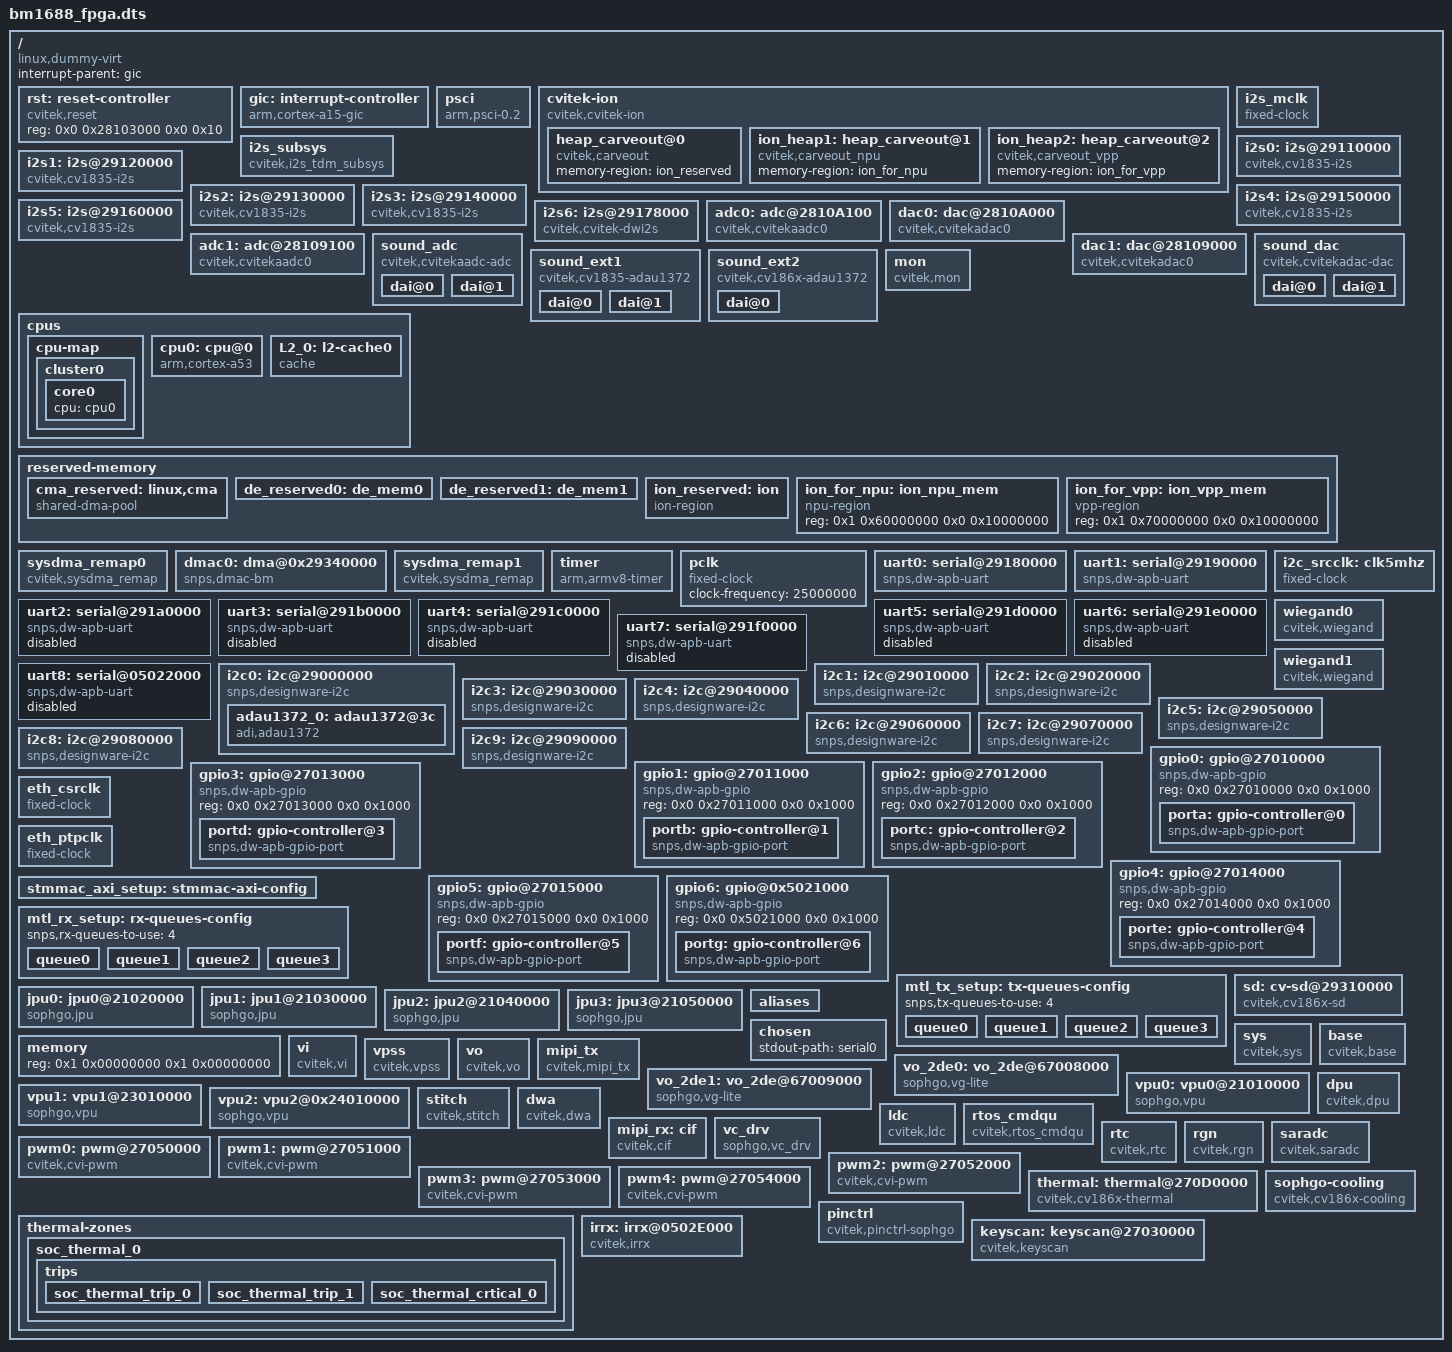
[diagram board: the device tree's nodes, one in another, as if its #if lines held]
#include <dt-bindings/interrupt-controller/arm-gic.h>
#include <dt-bindings/gpio/gpio.h>
#include <dt-bindings/reset/cv186x-resets.h>
#include <dt-bindings/dma/cv186x-dmamap.h>
#include <dt-bindings/input/input.h>

/dts-v1/;

/memreserve/	0x100000000 0x0000000000040000; // ATF BL31 + BL32

#include "soph-clocks.dtsi"
/ {
	compatible = "linux,dummy-virt";
	#size-cells = <0x2>;
	#address-cells = <0x2>;
	interrupt-parent = <&gic>;

	rst: reset-controller {
		#reset-cells = <1>;
		compatible = "cvitek,reset";
		reg = <0x0 0x28103000 0x0 0x10>;
	};

	gic: interrupt-controller {
		compatible = "arm,cortex-a15-gic";
		ranges;
		#size-cells = <0x2>;
		#address-cells = <0x2>;
		interrupt-controller;
		#interrupt-cells = <0x3>;
		reg = <0x0 0x50001000 0x0 0x1000>,
			  <0x0 0x50002000 0x0 0x2000>;
	};

	psci {
		migrate = <0xc4000005>;
		cpu_on = <0xc4000003>;
		cpu_off = <0x84000002>;
		cpu_suspend = <0xc4000001>;
		sys_poweroff = <0x84000008>;
		sys_reset = <0x84000009>;
		method = "smc";
		compatible = "arm,psci-0.2", "arm,psci";
	};

	cvitek-ion {
		compatible = "cvitek,cvitek-ion";

		heap_carveout@0 {
			compatible = "cvitek,carveout";
			memory-region = <&ion_reserved>;
		};
		#ifndef __UBOOT__
		ion_heap1: heap_carveout@1 {
			compatible = "cvitek,carveout_npu";
			memory-region = <&ion_for_npu>;
		};

		ion_heap2: heap_carveout@2 {
			compatible = "cvitek,carveout_vpp";
			memory-region = <&ion_for_vpp>;
		};
		#endif
	};

	i2s_mclk: i2s_mclk {
		clock-output-names = "i2s_mclk";
		clock-frequency = <24576000>;
		#clock-cells = <0x0>;
		compatible = "fixed-clock";
	};

	i2s_subsys {
		compatible = "cvitek,i2s_tdm_subsys";
		reg = <0x0 0x29100000 0x0 0x10000>;
		clocks = <&i2s_mclk>, <&clk CV186X_CLK_A0PLL>,
			<&clk CV186X_CLK_AUD0>, <&clk CV186X_CLK_AUD1>,
			<&clk CV186X_CLK_AUD2>, <&clk CV186X_CLK_AUD3>,
			<&clk CV186X_CLK_AUD4>, <&clk CV186X_CLK_AUD5>;
		clock-names = "i2sclk", "clk_a0pll",
			"clk_sdma_aud0", "clk_sdma_aud1",
			"clk_sdma_aud2", "clk_sdma_aud3",
			"clk_sdma_aud4", "clk_sdma_aud5";
		master_base = <0x29120000>; /* I2S1 is master, only useful while using multi I2S IPs work on same IO */
	};

	i2s0: i2s@29110000 {
		compatible = "cvitek,cv1835-i2s";
		reg = <0x0 0x29110000 0x0 0x10000>;
		clocks = <&i2s_mclk 0>;
		clock-names = "i2sclk";

		interrupts = <GIC_SPI 121 IRQ_TYPE_LEVEL_HIGH>;
		dev-id = <0>;
		#sound-dai-cells = <0>;
		dmas = <&dmac0 0 1 1>; /* read channel */
		dma-names = "rx";
		capability = "rx"; /* I2S0 connect to internal ADC as RX */
		mclk_out = "false";
	};

	i2s1: i2s@29120000 {
		compatible = "cvitek,cv1835-i2s";
		reg = <0x0 0x29120000 0x0 0x10000>;
		clocks = <&i2s_mclk 0>;
		clock-names = "i2sclk";

		interrupts = <GIC_SPI 122 IRQ_TYPE_LEVEL_HIGH>;
		dev-id = <1>;
		#sound-dai-cells = <0>;
		dmas = <&dmac0 2 1 1>; /* read channel */
		dma-names = "rx";
		capability = "rx";
		mclk_out = "false";
	};

	i2s2: i2s@29130000 {
		compatible = "cvitek,cv1835-i2s";
		reg = <0x0 0x29130000 0x0 0x10000>;
		clocks = <&i2s_mclk 0>;
		clock-names = "i2sclk";

		interrupts = <GIC_SPI 123 IRQ_TYPE_LEVEL_HIGH>;
		dev-id = <2>;
		#sound-dai-cells = <0>;
		dmas = <&dmac0 1 1 1>; /* write channel */
		dma-names = "tx";
		capability = "tx";
		mclk_out = "true";
	};

	i2s3: i2s@29140000 {
		compatible = "cvitek,cv1835-i2s";
		reg = <0x0 0x29140000 0x0 0x10000>;
		clocks = <&i2s_mclk 0>;
		clock-names = "i2sclk";

		interrupts = <GIC_SPI 124 IRQ_TYPE_LEVEL_HIGH>;
		dev-id = <3>;
		#sound-dai-cells = <0>;
		dmas = <&dmac0 4 1 1>; /* write channel */
		dma-names = "tx";
		capability = "tx"; /* I2S3 connect to internal DAC as TX */
		mclk_out = "true";
	};

	i2s4: i2s@29150000 {
		compatible = "cvitek,cv1835-i2s";
		reg = <0x0 0x29150000 0x0 0x10000>;
		clocks = <&i2s_mclk 0>;
		clock-names = "i2sclk";

		interrupts = <GIC_SPI 125 IRQ_TYPE_LEVEL_HIGH>;
		dev-id = <4>;
		#sound-dai-cells = <0>;
		dmas = <&dmac0 2 1 1>; /* read channel */
		dma-names = "rx";
		capability = "rx"; /* I2S0 connect to internal ADC as RX */
		mclk_out = "false";
	};

	i2s5: i2s@29160000 {
		compatible = "cvitek,cv1835-i2s";
		reg = <0x0 0x29160000 0x0 0x10000>;
		clocks = <&i2s_mclk 0>;
		clock-names = "i2sclk";

		interrupts = <GIC_SPI 126 IRQ_TYPE_LEVEL_HIGH>;
		dev-id = <5>;
		#sound-dai-cells = <0>;
		dmas = <&dmac0 3 1 1>; /* write channel */
		dma-names = "tx";
		capability = "tx"; /* I2S3 connect to internal DAC as TX */
		mclk_out = "true";
	};

	i2s6: i2s@29178000 {
		compatible = "cvitek,cvitek-dwi2s";
		reg = <0x0 0x29178000 0x0 0x400>;
		clocks = <&i2s_mclk 0>;
		clock-names = "i2sclk";

		interrupts = <GIC_SPI 127 IRQ_TYPE_LEVEL_HIGH>;
		dev-id = <6>;
		#sound-dai-cells = <0>;
		dmas = <&dmac0 4 1 1>; /* read channel */
		dma-names = "tx";
		capability = "tx"; /* I2S0 connect to internal ADC as RX */
		mclk_out = "true";
	};

	adc0: adc@2810A100 {
		compatible = "cvitek,cvitekaadc0";
		reg = <0x0 0x2810A100 0x0 0x100>;
		clocks = <&i2s_mclk 0>;
		clock-names = "i2sclk";
		clk_source = <0x29140000>; /* MCLK source is I2S3 */
	};

	dac0: dac@2810A000 {
		compatible = "cvitek,cvitekadac0";
		reg = <0x0 0x2810A000 0x0 0x100>;
		clocks = <&i2s_mclk 0>;
		clock-names = "i2sclk";
	};

	adc1: adc@28109100 {
		compatible = "cvitek,cvitekaadc0";
		reg = <0x0 0x28109100 0x0 0x100>;
		clocks = <&i2s_mclk 0>;
		clock-names = "i2sclk";
		clk_source = <0x29160000>; /* MCLK source is I2S3 */
	};

	dac1: dac@28109000 {
		compatible = "cvitek,cvitekadac0";
		reg = <0x0 0x28109000 0x0 0x100>;
		clocks = <&i2s_mclk 0>;
		clock-names = "i2sclk";
	};

	sound_adc {
		compatible = "cvitek,cvitekaadc-adc";
		cvi,model = "CV182XA";
		cvi,card_name = "cv186x_adc";
		dai@0 {
			//adc0:2810A100 - i2s0:29110000;
		};
		dai@1 {
			//adc1:28109100 - i2s4:29150000;
		};
	};

	sound_dac {
		compatible = "cvitek,cvitekadac-dac";
		cvi,model = "CV182XA";
		cvi,card_name = "cv186x_dac";
		dai@0 {
			//dac0:2810A000 - i2s3:29140000;
		};
		dai@1 {
			//dac0:28109000 - i2s5:29160000;
		};
	};

	sound_ext1 {
		compatible = "cvitek,cv1835-adau1372";
		cvi,model = "CV1835";
		cvi,mode = "I2S";
		cvi,fmt = "IBNF";
		cvi,card_name = "cvi_sound_card_0";
		cvi,slot_no=<2>;

		dai@0 {
			cvi,dai_name = "cv1835-i2s-2";
			cvi,stream_name = "adau1372-aif";
#if 0
			cvi,cpu_dai_name = "29130000.i2s";
			cvi,codec_dai_name = "adau1372-aif";
			cvi,platform_name = "29130000.i2s";
			cvi,codec_name = "adau1372.0-003c";
#endif
			cvi,role = "master";
		};

		dai@1 {
			cvi,dai_name = "cv1835-i2s-1";
			cvi,stream_name = "adau1372-aif";
#if 0
			cvi,cpu_dai_name = "29120000.i2s";
			cvi,codec_dai_name = "adau1372-aif";
			cvi,platform_name = "29120000.i2s";
			cvi,codec_name = "adau1372.0-003c";
#endif
			cvi,role = "slave";
		};
	};


	sound_ext2 {
		compatible = "cvitek,cv186x-adau1372";
		cvi,model = "CV1835";
		cvi,mode = "I2S";
		cvi,fmt = "NBNF";
		cvi,card_name = "cvi_cv186x_dw";
		cvi,slot_no=<2>;

		dai@0 {
			cvi,stream_name = "adau1372-aif";
			cvi,role = "master";
		};

	};

	cpus {
		#size-cells = <0x0>;
		#address-cells = <0x1>;

		cpu-map {
			cluster0 {
				core0 {
					cpu = <&cpu0>;
				};
			};
		};

		cpu0: cpu@0 {
			reg = <0x0>;
			enable-method = "psci";
			compatible = "arm,cortex-a53";
			device_type = "cpu";
			next-level-cache = <&L2_0>;
		};

		L2_0: l2-cache0 {
			compatible = "cache";
			cache-unified;
			cache-level = <2>;
		};
	};

	mon {
		compatible = "cvitek,mon";
		reg-names = "pcmon", "ddr_ctrl", "ddr_phyd", "ddr_aximon_real", "ddr_aximon_offline", "ddr_aximon_bulk", "ddr_top";
		reg = <0x0 0x01040000 0x0 0x1000>,
					<0x0 0x70004000 0x0 0x1000>,
					<0x0 0x70006000 0x0 0x1000>,
					<0x0 0x6fff3000 0x0 0x1000>,
					<0x0 0x6fff4000 0x0 0x1000>,
					<0x0 0x6fff5000 0x0 0x1000>,
					<0x0 0x7000A000 0x0 0x1000>;
		interrupts = <GIC_SPI 77 IRQ_TYPE_EDGE_RISING>;
	};

	/*pmu_a53 {
		compatible = "arm,cortex-a53-pmu";
		interrupts = <GIC_SPI 196 IRQ_TYPE_LEVEL_HIGH>,
			     <GIC_SPI 197 IRQ_TYPE_LEVEL_HIGH>,
			     <GIC_SPI 198 IRQ_TYPE_LEVEL_HIGH>,
			     <GIC_SPI 199 IRQ_TYPE_LEVEL_HIGH>,
			     <GIC_SPI 208 IRQ_TYPE_LEVEL_HIGH>,
			     <GIC_SPI 209 IRQ_TYPE_LEVEL_HIGH>,
			     <GIC_SPI 210 IRQ_TYPE_LEVEL_HIGH>,
			     <GIC_SPI 211 IRQ_TYPE_LEVEL_HIGH>;
	};*/

	reserved-memory {
		#address-cells = <0x2>;
		#size-cells = <0x2>;
		ranges;

		cma_reserved: linux,cma {
			compatible = "shared-dma-pool";
			reusable;
			//size = <0x0 0x200000>; // 2MB
			size = <0x0 0x80000000>; // 2GB
			alignment = <0x0 0x100000>; // 1MB
			linux,cma-default;
		};

		de_reserved0: de_mem0 {
			reg = <0x1 0x10000000 0x0 0x8000000>; // 128M, for 2de
			no-map;
		};

		de_reserved1: de_mem1 {
			reg = <0x1 0x18000000 0x0 0x8000000>; // 128M, for 2de
			no-map;
		};

		ion_reserved: ion {
			compatible = "ion-region";
			alloc-ranges = <0x1 0x40000000 0 0x20000000>;
			size = <0x0 0x20000000>; // 512MB
		};
		#ifndef __UBOOT__
		ion_for_npu: ion_npu_mem {
			compatible = "npu-region";
			reg = <0x1 0x60000000 0x0 0x10000000>; // 256M
		};

		ion_for_vpp: ion_vpp_mem {
			compatible = "vpp-region";
			reg = <0x1 0x70000000 0x0 0x10000000>; // 256M, for VPP/JPU
		};
		#endif
	};

	sysdma_remap0 {
		compatible = "cvitek,sysdma_remap";
		reg = <0x0 0x28100154 0x0 0x10>;
		ch-remap = <CVI_I2S0_RX CVI_I2S2_TX CVI_I2S1_RX CVI_I2S1_TX
					CVI_I2S_dw_RX CVI_I2S_dw_TX CVI_I2S2_RX CVI_I2S3_TX>;
		int_mux_base = <0x281002A0>;
		int_mux = <0x1FF>; /* enable bit [0..8] for CPU0(CA53) */
	};

	dmac0: dma@0x29340000 {
		compatible = "snps,dmac-bm";
		reg = <0x0 0x29340000 0x0 0x1000>;
		clock-names = "clk_sdma_axi";
		clocks = <&clk CV186X_CLK_SDMA0_AXI>;

		interrupts = <GIC_SPI 98 IRQ_TYPE_LEVEL_HIGH>;
		dma-channels = /bits/ 8 <8>;
		#dma-cells = <3>;
		dma-requests = /bits/ 8 <16>;
		chan_allocation_order = /bits/ 8 <0>;
		chan_priority = /bits/ 8 <1>;
		block_size = <1024>;
		dma-masters = /bits/ 8 <2>;
		data-width = <4 4>; /* bytes */
		axi_tr_width = <4>; /* bytes */
		block-ts = <15>;
	};

	sysdma_remap1 {
		compatible = "cvitek,sysdma_remap";
		reg = <0x0 0x28100164 0x0 0x10>;
		ch-remap = <CVI_I2S4_RX CVI_SPI_NAND CVI_SPI_NAND CVI_I2S5_TX
					CVI_SPI0_TX CVI_SPI0_TX CVI_SPI1_TX CVI_SPI1_TX>;
		int_mux_base = <0x281002A4>;
		int_mux = <0x1FF>; /* enable bit [0..8] for CPU0(CA53) */
	};
#if 0
	dmac1: dma@0x29350000 {
		compatible = "snps,dmac-bm";
		reg = <0x0 0x29350000 0x0 0x1000>;
		clock-names = "clk_sdma_axi";
		clocks = <&clk CV186X_CLK_SDMA1_AXI>;

		interrupts = <GIC_SPI 99 IRQ_TYPE_LEVEL_HIGH>;
		dma-channels = /bits/ 8 <8>;
		#dma-cells = <3>;
		dma-requests = /bits/ 8 <16>;
		chan_allocation_order = /bits/ 8 <0>;
		chan_priority = /bits/ 8 <1>;
		block_size = <1024>;
		dma-masters = /bits/ 8 <2>;
		data-width = <4 4>; /* bytes */
		axi_tr_width = <4>; /* bytes */
		block-ts = <15>;
	};
#endif
	timer {
		interrupts = <GIC_PPI 13 (GIC_CPU_MASK_SIMPLE(1) | IRQ_TYPE_LEVEL_LOW)>,
			<GIC_PPI 14 (GIC_CPU_MASK_SIMPLE(1) | IRQ_TYPE_LEVEL_LOW)>,
			<GIC_PPI 11 (GIC_CPU_MASK_SIMPLE(1) | IRQ_TYPE_LEVEL_LOW)>,
			<GIC_PPI 10 (GIC_CPU_MASK_SIMPLE(1) | IRQ_TYPE_LEVEL_LOW)>;
		always-on;
		clock-frequency = <5000000>;
		compatible = "arm,armv8-timer";
	};


	pclk: pclk {
		#clock-cells = <0>;
		compatible = "fixed-clock";
		clock-frequency = <25000000>;
	};

	uart0: serial@29180000 {
		compatible = "snps,dw-apb-uart";
		reg = <0x0 0x29180000 0x0 0x1000>;
		clock-frequency = <5000000>;
		current-speed = <38400>;
		interrupts = <GIC_SPI 128 IRQ_TYPE_LEVEL_HIGH>;
		reg-shift = <2>;
		reg-io-width = <4>;
		status = "okay";
	};

	uart1: serial@29190000 {
		compatible = "snps,dw-apb-uart";
		reg = <0x0 0x29190000 0x0 0x1000>;
		clock-frequency = <5000000>;
		current-speed = <38400>;
		interrupts = <GIC_SPI 129 IRQ_TYPE_LEVEL_HIGH>;
		reg-shift = <2>;
		reg-io-width = <4>;
		status = "okay";
	};

	uart2: serial@291a0000 {
		compatible = "snps,dw-apb-uart";
		reg = <0x0 0x291a0000 0x0 0x1000>;
		clock-frequency = <5000000>;
		current-speed = <38400>;
		interrupts = <GIC_SPI 130 IRQ_TYPE_LEVEL_HIGH>;
		reg-shift = <2>;
		reg-io-width = <4>;
		status = "disable";
	};

	uart3: serial@291b0000 {
		compatible = "snps,dw-apb-uart";
		reg = <0x0 0x291b0000 0x0 0x1000>;
		clock-frequency = <5000000>;
		current-speed = <38400>;
		interrupts = <GIC_SPI 131 IRQ_TYPE_LEVEL_HIGH>;
		reg-shift = <2>;
		reg-io-width = <4>;
		status = "disable";
	};

	uart4: serial@291c0000 {
		compatible = "snps,dw-apb-uart";
		reg = <0x0 0x291c0000 0x0 0x1000>;
		clock-frequency = <5000000>;
		current-speed = <38400>;
		interrupts = <GIC_SPI 132 IRQ_TYPE_LEVEL_HIGH>;
		reg-shift = <2>;
		reg-io-width = <4>;
		status = "disable";
	};

	uart5: serial@291d0000 {
		compatible = "snps,dw-apb-uart";
		reg = <0x0 0x291d0000 0x0 0x1000>;
		clock-frequency = <5000000>;
		current-speed = <38400>;
		interrupts = <GIC_SPI 133 IRQ_TYPE_LEVEL_HIGH>;
		reg-shift = <2>;
		reg-io-width = <4>;
		status = "disable";
	};

	uart6: serial@291e0000 {
		compatible = "snps,dw-apb-uart";
		reg = <0x0 0x291e0000 0x0 0x1000>;
		clock-frequency = <5000000>;
		current-speed = <38400>;
		interrupts = <GIC_SPI 134 IRQ_TYPE_LEVEL_HIGH>;
		reg-shift = <2>;
		reg-io-width = <4>;
		status = "disable";
	};

	uart7: serial@291f0000 {
		compatible = "snps,dw-apb-uart";
		reg = <0x0 0x291f0000 0x0 0x1000>;
		clock-frequency = <5000000>;
		current-speed = <38400>;
		interrupts = <GIC_SPI 135 IRQ_TYPE_LEVEL_HIGH>;
		reg-shift = <2>;
		reg-io-width = <4>;
		status = "disable";
	};

	uart8: serial@05022000 {
		compatible = "snps,dw-apb-uart";
		reg = <0x0 0x05022000 0x0 0x1000>;
		clock-frequency = <5000000>;
		current-speed = <38400>;
		interrupts = <GIC_SPI 77 IRQ_TYPE_LEVEL_HIGH>;
		reg-shift = <2>;
		reg-io-width = <4>;
		status = "disable";
	};

	i2c_srcclk: clk5mhz {
		clock-output-names = "clk5mhz";
		clock-frequency = <5000000>;
		#clock-cells = <0x0>;
		compatible = "fixed-clock";
	};

	i2c0: i2c@29000000 {
		compatible = "snps,designware-i2c";
		clocks = <&i2c_srcclk>;
		reg = <0x0 0x29000000 0x0 0x1000>;
		interrupts = <GIC_SPI 106 IRQ_TYPE_LEVEL_HIGH>;
		clock-frequency = <100000>;

		#size-cells = <0x0>;
		#address-cells = <0x1>;
		//resets = <&rst RST_I2C0>;
		// reset-names = "i2c0";

		adau1372_0: adau1372@3c{
			compatible = "adi,adau1372";
			reg = <0x3c>;
			clocks = <&i2s_mclk>;
			clock-names = "mclk";
		};
	};

	wiegand0 {
		compatible = "cvitek,wiegand";
		reg-names = "wiegand";
		reg = <0x0 0x27020000 0x0 0x1000>;
		// clocks = <&clk CV181X_CLK_WGN>, <&clk CV181X_CLK_WGN0>;
		// clock-names = "clk_wgn", "clk_wgn1";
		interrupts = <GIC_SPI 149 IRQ_TYPE_LEVEL_HIGH>;
		resets = <&rst RST_WGN0>;
		reset-names = "res_wgn";
	};

	wiegand1 {
		compatible = "cvitek,wiegand";
		reg-names = "wiegand";
		reg = <0x0 0x27021000 0x0 0x1000>;
		// clocks = <&clk CV181X_CLK_WGN>, <&clk CV181X_CLK_WGN1>;
		// clock-names = "clk_wgn", "clk_wgn1";
		interrupts = <GIC_SPI 150 IRQ_TYPE_LEVEL_HIGH>;
		resets = <&rst RST_WGN1>;
		reset-names = "res_wgn";
	};

	i2c1: i2c@29010000 {
		compatible = "snps,designware-i2c";
		clocks = <&i2c_srcclk>;
		reg = <0x0 0x29010000 0x0 0x1000>;
		interrupts = <GIC_SPI 107 IRQ_TYPE_LEVEL_HIGH>;
		clock-frequency = <100000>;

		#size-cells = <0x0>;
		#address-cells = <0x1>;
		//resets = <&rst RST_I2C1>;
		// reset-names = "i2c1";
	};

	i2c2: i2c@29020000 {
		compatible = "snps,designware-i2c";
		clocks = <&i2c_srcclk>;
		reg = <0x0 0x29020000 0x0 0x1000>;
		interrupts = <GIC_SPI 108 IRQ_TYPE_LEVEL_HIGH>;
		clock-frequency = <100000>;

		#size-cells = <0x0>;
		#address-cells = <0x1>;
		//resets = <&rst RST_I2C2>;
		// reset-names = "i2c2";
	};

	i2c3: i2c@29030000 {
		compatible = "snps,designware-i2c";
		clocks = <&i2c_srcclk>;
		reg = <0x0 0x29030000 0x0 0x1000>;
		interrupts = <GIC_SPI 109 IRQ_TYPE_LEVEL_HIGH>;
		clock-frequency = <100000>;

		#size-cells = <0x0>;
		#address-cells = <0x1>;
		//resets = <&rst RST_I2C3>;
		// reset-names = "i2c3";
	};

	i2c4: i2c@29040000 {
		compatible = "snps,designware-i2c";
		clocks = <&i2c_srcclk>;
		reg = <0x0 0x29040000 0x0 0x1000>;
		interrupts = <GIC_SPI 110 IRQ_TYPE_LEVEL_HIGH>;
		clock-frequency = <100000>;

		#size-cells = <0x0>;
		#address-cells = <0x1>;
		//resets = <&rst RST_I2C4>;
		// reset-names = "i2c4";
	};

	i2c5: i2c@29050000 {
		compatible = "snps,designware-i2c";
		clocks = <&i2c_srcclk>;
		reg = <0x0 0x29050000 0x0 0x1000>;
		interrupts = <GIC_SPI 111 IRQ_TYPE_LEVEL_HIGH>;
		clock-frequency = <100000>;

		#size-cells = <0x0>;
		#address-cells = <0x1>;
		//resets = <&rst RST_I2C5>;
		// reset-names = "i2c5";
	};

	i2c6: i2c@29060000 {
		compatible = "snps,designware-i2c";
		clocks = <&i2c_srcclk>;
		reg = <0x0 0x29060000 0x0 0x1000>;
		interrupts = <GIC_SPI 112 IRQ_TYPE_LEVEL_HIGH>;
		clock-frequency = <100000>;

		#size-cells = <0x0>;
		#address-cells = <0x1>;
		//resets = <&rst RST_I2C6>;
		// reset-names = "i2c6";
	};

	i2c7: i2c@29070000 {
		compatible = "snps,designware-i2c";
		clocks = <&i2c_srcclk>;
		reg = <0x0 0x29070000 0x0 0x1000>;
		interrupts = <GIC_SPI 113 IRQ_TYPE_LEVEL_HIGH>;
		clock-frequency = <100000>;

		#size-cells = <0x0>;
		#address-cells = <0x1>;
		//resets = <&rst RST_I2C7>;
		// reset-names = "i2c7";
	};

	i2c8: i2c@29080000 {
		compatible = "snps,designware-i2c";
		clocks = <&i2c_srcclk>;
		reg = <0x0 0x29080000 0x0 0x1000>;
		interrupts = <GIC_SPI 114 IRQ_TYPE_LEVEL_HIGH>;
		clock-frequency = <100000>;

		#size-cells = <0x0>;
		#address-cells = <0x1>;
		//resets = <&rst RST_I2C8>;
		// reset-names = "i2c8";
	};

	i2c9: i2c@29090000 {
		compatible = "snps,designware-i2c";
		clocks = <&i2c_srcclk>;
		reg = <0x0 0x29090000 0x0 0x1000>;
		interrupts = <GIC_SPI 115 IRQ_TYPE_LEVEL_HIGH>;
		clock-frequency = <100000>;

		#size-cells = <0x0>;
		#address-cells = <0x1>;
		//resets = <&rst RST_I2C9>;
		// reset-names = "i2c9";
	};

	gpio0: gpio@27010000 {
		compatible = "snps,dw-apb-gpio";
		reg = <0x0 0x27010000 0x0 0x1000>;
		#address-cells = <1>;
		#size-cells = <0>;

		porta: gpio-controller@0 {
			compatible = "snps,dw-apb-gpio-port";
			bank-name = "porta";
			gpio-controller;
			#gpio-cells = <2>;
			snps,nr-gpios = <32>;
			reg = <0>;
			interrupts = <GIC_SPI 143 IRQ_TYPE_LEVEL_HIGH>;
		};
	};

	gpio1: gpio@27011000 {
		compatible = "snps,dw-apb-gpio";
		reg = <0x0 0x27011000 0x0 0x1000>;
		#address-cells = <1>;
		#size-cells = <0>;

		portb: gpio-controller@1 {
			compatible = "snps,dw-apb-gpio-port";
			bank-name = "portb";
			gpio-controller;
			#gpio-cells = <2>;
			snps,nr-gpios = <32>;
			reg = <0>;
			interrupts = <GIC_SPI 144 IRQ_TYPE_LEVEL_HIGH>;
		};
	};

	gpio2: gpio@27012000 {
		compatible = "snps,dw-apb-gpio";
		reg = <0x0 0x27012000 0x0 0x1000>;
		#address-cells = <1>;
		#size-cells = <0>;

		portc: gpio-controller@2 {
			compatible = "snps,dw-apb-gpio-port";
			bank-name = "portc";
			gpio-controller;
			#gpio-cells = <2>;
			snps,nr-gpios = <32>;
			reg = <0>;
			interrupts = <GIC_SPI 145 IRQ_TYPE_LEVEL_HIGH>;
		};
	};

	gpio3: gpio@27013000 {
		compatible = "snps,dw-apb-gpio";
		reg = <0x0 0x27013000 0x0 0x1000>;
		#address-cells = <1>;
		#size-cells = <0>;

		portd: gpio-controller@3 {
			compatible = "snps,dw-apb-gpio-port";
			bank-name = "portd";
			gpio-controller;
			#gpio-cells = <2>;
			snps,nr-gpios = <32>;
			reg = <0>;
			interrupts = <GIC_SPI 146 IRQ_TYPE_LEVEL_HIGH>;
		};
	};

	gpio4: gpio@27014000 {
		compatible = "snps,dw-apb-gpio";
		reg = <0x0 0x27014000 0x0 0x1000>;
		#address-cells = <1>;
		#size-cells = <0>;

		porte: gpio-controller@4 {
			compatible = "snps,dw-apb-gpio-port";
			bank-name = "porte";
			gpio-controller;
			#gpio-cells = <2>;
			snps,nr-gpios = <32>;
			reg = <0>;
			interrupts = <GIC_SPI 147 IRQ_TYPE_LEVEL_HIGH>;
		};
	};

	gpio5: gpio@27015000 {
		compatible = "snps,dw-apb-gpio";
		reg = <0x0 0x27015000 0x0 0x1000>;
		#address-cells = <1>;
		#size-cells = <0>;

		portf: gpio-controller@5 {
			compatible = "snps,dw-apb-gpio-port";
			bank-name = "portf";
			gpio-controller;
			#gpio-cells = <2>;
			snps,nr-gpios = <32>;
			reg = <0>;
			interrupts = <GIC_SPI 148 IRQ_TYPE_LEVEL_HIGH>;
		};
	};

	gpio6: gpio@0x5021000 {
		compatible = "snps,dw-apb-gpio";
		reg = <0x0 0x5021000 0x0 0x1000>;
		#address-cells = <1>;
		#size-cells = <0>;

		portg: gpio-controller@6 {
			compatible = "snps,dw-apb-gpio-port";
			bank-name = "portg";
			gpio-controller;
			#gpio-cells = <2>;
			snps,nr-gpios = <32>;
			reg = <0>;
			interrupts = <GIC_SPI 76 IRQ_TYPE_LEVEL_HIGH>;
		};
	};

	eth_csrclk: eth_csrclk {
		clock-output-names = "eth_csrclk";
		clock-frequency = <250000000>;
		#clock-cells = <0x0>;
		compatible = "fixed-clock";
	};

	eth_ptpclk: eth_ptpclk {
		clock-output-names = "eth_ptpclk";
		clock-frequency = <50000000>;
		#clock-cells = <0x0>;
		compatible = "fixed-clock";
	};

	stmmac_axi_setup: stmmac-axi-config {
		snps,wr_osr_lmt = <1>;
		snps,rd_osr_lmt = <2>;
		snps,blen = <4 8 16 0 0 0 0>;
	};

	mtl_rx_setup: rx-queues-config {
		snps,rx-queues-to-use = <4>;
		queue0 {};
		queue1 {};
		queue2 {};
		queue3 {};
	};

	mtl_tx_setup: tx-queues-config {
		snps,tx-queues-to-use = <4>;
		queue0 {};
		queue1 {};
		queue2 {};
		queue3 {};
	};
#if 0
	ethernet0: ethernet@290e0000 {
		compatible = "bitmain,ethernet";
		reg = <0x0 0x290e0000 0x0 0x4000>;
		reg-names = "mac";
		interrupt-names = "macirq";
		interrupts = <GIC_SPI 104 IRQ_TYPE_LEVEL_HIGH>;
		/*
		//bm1684x
		clock-names = "clk_tx", "gate_clk_tx", "stmmaceth", "ptp_ref", "gate_clk_ref";
		clocks = <&div_clk DIV_CLK_FPLL_TX_ETH0>,
			   <&div_clk GATE_CLK_ETH0_TX>,
			   <&div_clk GATE_CLK_AXI6_ETH0>,
			   <&div_clk GATE_CLK_PTP_REF_I_ETH0>,
			   <&div_clk GATE_CLK_REF_ETH0>;
		//cv183x
		clock-names = "stmmaceth", "ptp_ref", "clk_500m_eth", "clk_axi4_eth";
		clocks = <&eth_csrclk>, <&eth_ptpclk>, <&clk CV1835_CLK_500M_ETH0>, <&clk CV1835_CLK_AXI4_ETH0>;*/
		//cv182x
		clock-names = "stmmaceth", "ptp_ref";
		clocks = <&eth_csrclk>, <&eth_ptpclk>;
#ifdef __UBOOT__
		phy-reset-gpios = <&portd 21 0>;
#endif
		/* no hash filter and perfect filter support */
		snps,multicast-filter-bins = <0>;
		snps,perfect-filter-entries = <1>;

		snps,txpbl = <32>;
		snps,rxpbl = <32>;
		snps,aal;

		snps,axi-config = <&stmmac_axi_setup>;
		snps,mtl-rx-config = <&mtl_rx_setup>;
		snps,mtl-tx-config = <&mtl_tx_setup>;

		phy-mode = "rgmii-id";
		max-speed = <100>;

	};
#endif
	sd:cv-sd@29310000 {
#ifdef	__UBOOT__
		compatible = "cvitek,cv186x-sd";
#else
		compatible = "cvitek,cv186x-fpga-sd";
#endif
		reg = <0x0 0x29310000 0x0 0x10000>;
		reg-names = "core_mem";
		interrupts = <GIC_SPI 90 IRQ_TYPE_LEVEL_HIGH>;
		bus-width = <4>;
		//cap-sd-highspeed;
		//cap-mmc-highspeed;
		no-sdio;
		no-mmc;
		no-1-8-v;
		//broken-cd;
		src-frequency = <5000000>;
		min-frequency = <200000>;
		max-frequency = <4000000>;
		reset_tx_rx_phy;
		reset-names = "sdhci";
		64_addressing;
	};

	jpu0: jpu0@21020000 {
	    compatible = "sophgo,jpu";
	    reg =  <0x0 0x21020000 0x0 0x10000>;
	    interrupts =   <GIC_SPI 46 IRQ_TYPE_EDGE_RISING>;
	    dev-id = <0>;
	};

	jpu1: jpu1@21030000 {
	    compatible = "sophgo,jpu";
	    reg =  <0x0 0x21030000 0x0 0x10000>;
	    interrupts =   <GIC_SPI 47 IRQ_TYPE_EDGE_RISING>;
	    dev-id = <1>;
	};

	jpu2: jpu2@21040000 {
	    compatible = "sophgo,jpu";
	    reg =  <0x0 0x21040000 0x0 0x10000>;
	    interrupts =   <GIC_SPI 48 IRQ_TYPE_EDGE_RISING>;
	    dev-id = <2>;
	};

	jpu3: jpu3@21050000 {
	    compatible = "sophgo,jpu";
	    reg =  <0x0 0x21050000 0x0 0x10000>;
	    interrupts =   <GIC_SPI 49 IRQ_TYPE_EDGE_RISING>;
	    dev-id = <3>;
	};

	memory {
		reg = <0x1 0x00000000 0x1 0x00000000>;	//4G
		device_type = "memory";
	};

	aliases {
		serial0 = &uart0;
		serial1 = &uart1;
		serial2 = &uart2;
		serial3 = &uart3;
		serial4 = &uart4;
		serial5 = &uart5;
		serial6 = &uart6;
		serial7 = &uart7;
	};

	chosen {
		stdout-path = "serial0"; // "serial0:115200n8", no arguments means no re-initialization
	};

	sys {
		compatible = "cvitek,sys";
		reg = <0x0 0x680be000 0x0 0x1000>,<0x0 0x680bc000 0x0 0x1000>;
		interrupts = <GIC_SPI 5 IRQ_TYPE_LEVEL_HIGH>;
		interrupt-names = "vi_cdma";
	};

	base {
		compatible = "cvitek,base";
	};

	vi {
		compatible = "cvitek,vi";
		reg = <0x0 0x68000000 0x0 0x80000>;
		interrupts = <GIC_SPI 17 IRQ_TYPE_LEVEL_HIGH>;
		interrupt-names = "isp";
	};

	vpss {
		compatible = "cvitek,vpss";
		reg =   <0x0 0x68080000 0x0 0x10000>,	//vpss_v
				<0x0 0x23020000 0x0 0x20000>,	//vpss_t0t1
				<0x0 0x24020000 0x0 0x20000>,	//vpss_t2t3
				<0x0 0x67010000 0x0 0x8000>;	//vpss_d
		interrupts = <GIC_SPI 23 IRQ_TYPE_LEVEL_HIGH>,
					<GIC_SPI 24 IRQ_TYPE_LEVEL_HIGH>,
					<GIC_SPI 25 IRQ_TYPE_LEVEL_HIGH>,
					<GIC_SPI 26 IRQ_TYPE_LEVEL_HIGH>,
					<GIC_SPI 40 IRQ_TYPE_LEVEL_HIGH>,
					<GIC_SPI 41 IRQ_TYPE_LEVEL_HIGH>,
					<GIC_SPI 43 IRQ_TYPE_LEVEL_HIGH>,
					<GIC_SPI 44 IRQ_TYPE_LEVEL_HIGH>,
					<GIC_SPI 31 IRQ_TYPE_LEVEL_HIGH>,
					<GIC_SPI 32 IRQ_TYPE_LEVEL_HIGH>;
		interrupt-names = "vpss_v0","vpss_v1","vpss_v2","vpss_v3",
						"vpss_t0","vpss_t1","vpss_t2","vpss_t3",
						"vpss_d0","vpss_d1";
	};

	vo {
		compatible = "cvitek,vo";
		reg = <0x0 0x67000000 0x0 0xD000>;
		reg-names = "vo_sys";
		interrupts = <GIC_SPI 33 IRQ_TYPE_LEVEL_HIGH>,
					<GIC_SPI 34 IRQ_TYPE_LEVEL_HIGH>;
		interrupt-names = "disp0", "disp1";
	};

	mipi_tx {
		compatible = "cvitek,mipi_tx";
	};

	vo_2de0: vo_2de@67008000 {
		compatible = "sophgo,vg-lite", "sophgo,vg-lite0";
		memory-region = <&de_reserved0>;
		interrupt-parent = <&gic>;
		interrupts = <GIC_SPI 27 IRQ_TYPE_LEVEL_HIGH>,
					<GIC_SPI 27 IRQ_TYPE_LEVEL_HIGH>;
		interrupt-names = "vo_2de_irq0", "vo_2de0";
		reg = <0x0 0x67008000 0x0 0x00001000>;
		reg-names = "iobase_vg";
		dev-id = <0>;
	};

	vo_2de1: vo_2de@67009000 {
		compatible = "sophgo,vg-lite", "sophgo,vg-lite1";
		memory-region = <&de_reserved1>;
		interrupt-parent = <&gic>;
		interrupts = <GIC_SPI 28 IRQ_TYPE_LEVEL_HIGH>,
					<GIC_SPI 28 IRQ_TYPE_LEVEL_HIGH>;
		interrupt-names = "vo_2de_irq1", "vo_2de1";
		reg = <0x0 0x67009000 0x0 0x00001000>;
		reg-names = "iobase_vg";
		dev-id = <1>;
	};

	vpu0: vpu0@21010000 {
         compatible = "sophgo,vpu";
         reg = 	<0x0 0x21010000 0x0 0x10000>;
		 dev-id = <0>;
         interrupts = 	<GIC_SPI 45 IRQ_TYPE_EDGE_RISING>;
	};


	vpu1: vpu1@23010000 {
         compatible = "sophgo,vpu";
         reg = 	<0x0 0x23010000 0x0 0x10000>;
		 dev-id = <1>;
         interrupts = 	<GIC_SPI 39 IRQ_TYPE_EDGE_RISING>;
	};

	vpu2: vpu2@0x24010000 {
         compatible = "sophgo,vpu";
		 dev-id = <2>;
         reg = 	<0x0 0x24010000 0x0 0x10000>;
         interrupts = 	<GIC_SPI 42 IRQ_TYPE_EDGE_RISING>;
	};

	dpu {
		compatible = "cvitek,dpu";
		reg = <0x0 0x680BA000 0x0 0x2000>;
		interrupts = <GIC_SPI 14 IRQ_TYPE_LEVEL_HIGH>;
		interrupt-names = "dpu";
	};

	stitch {
		compatible = "cvitek,stitch";
		reg = <0x0 0x680b8000 0x0 0x2000>;
		reg-names = "stitch";
		interrupts = <GIC_SPI 22 IRQ_TYPE_LEVEL_HIGH>;
		interrupt-names = "stitch";
	};

	dwa {
		compatible = "cvitek,dwa";
		reg = <0x0 0x680b4000 0x0 0x2000>, <0x0 0x680b6000 0x0 0x2000>;
		reg-names = "dwa0", "dwa1";
		interrupts = <GIC_SPI 15 IRQ_TYPE_LEVEL_HIGH>,
				<GIC_SPI 16 IRQ_TYPE_LEVEL_HIGH>;
		interrupt-names = "dwa0", "dwa1";
	};

	ldc {
		compatible = "cvitek,ldc";
		reg = <0x0 0x680b0000 0x0 0x2000>, <0x0 0x680b2000 0x0 0x2000>;
		reg-names = "ldc0", "ldc1";
		interrupts = <GIC_SPI 20 IRQ_TYPE_LEVEL_HIGH>,
				<GIC_SPI 21 IRQ_TYPE_LEVEL_HIGH>;
		interrupt-names = "ldc0", "ldc1";
	};
	rtos_cmdqu {
		compatible = "cvitek,rtos_cmdqu";
		reg = <0x0 0x270F0000 0x0 0x1000>;
		reg-names = "mailbox";
		interrupts = <GIC_SPI 163 IRQ_TYPE_LEVEL_HIGH>;
		interrupt-names = "mailbox";
	};

	mipi_rx: cif {
		compatible = "cvitek,cif";
		reg = <0x0 0x68100000 0x0 0x2000>, <0x0 0x68110000 0x0 0x1000>,
			<0x0 0x68102000 0x0 0x2000>, <0x0 0x68104000 0x0 0x2000>,
			<0x0 0x68106000 0x0 0x2000>, <0x0 0x68108000 0x0 0x2000>,
			<0x0 0x6810A000 0x0 0x2000>, <0x0 0x6810C000 0x0 0x2000>,
			<0x0 0x6810E000 0x0 0x2000>;

		reg-names = "csi_mac0", "csi_wrap0", "csi_mac1", "csi_mac2", "csi_mac3", "csi_mac4", "csi_mac5",
					"csi_mac_vi0", "csi_mac_vi1";
		interrupts = <GIC_SPI 6 IRQ_TYPE_LEVEL_HIGH>,
					<GIC_SPI 7 IRQ_TYPE_LEVEL_HIGH>,
					<GIC_SPI 8 IRQ_TYPE_LEVEL_HIGH>,
					<GIC_SPI 9 IRQ_TYPE_LEVEL_HIGH>,
					<GIC_SPI 10 IRQ_TYPE_LEVEL_HIGH>,
					<GIC_SPI 11 IRQ_TYPE_LEVEL_HIGH>,
					<GIC_SPI 12 IRQ_TYPE_LEVEL_HIGH>,
					<GIC_SPI 13 IRQ_TYPE_LEVEL_HIGH>;

		interrupt-names = "csi0", "csi1", "csi2", "csi3", "csi4", "csi5", "csi6", "csi7";
		//reset= <&rst RST_CSIPHY0>,<&rst RST_CSIPHY1>,
		//<&rst RST_CSIPHY0RST_APB>,<&rst RST_CSIPHY1RST_APB>;
		//reset-names = "phy0", "phy1","phy-apb0", "phy-apb1";
		//clocks = <&clk CV186X_CLK_CAM0>,
			//<&clk CV186X_CLK_CAM1>,
			//<&clk CV186X_CLK_CAM2>,
			//<&clk CV186X_CLK_SRC_VIP_SYS_0>,
			//<&clk CV186X_CLK_SRC_VIP_SYS_1>,
			//<&clk CV186X_CLK_SRC_VIP_SYS_2>,
			//<&clk CV186X_CLK_FPLL>;
		//clock-names = "clk_cam0", "clk_cam1",
			//"clk_cam2",
			//"clk_sys_0", "clk_sys_1", "clk_sys_2", "clk_fpll";
	};

	vc_drv {
         compatible = "sophgo,vc_drv";
         reg = 	<0x0 0x21020000 0x0 0x10000>,	//jpu
				<0x0 0x21030000 0x0 0x10000>,
				<0x0 0x21040000 0x0 0x10000>,
				<0x0 0x21050000 0x0 0x10000>,
				<0x0 0x21010000 0x0 0x10000>,	//vpu
				<0x0 0x23010000 0x0 0x10000>,
				<0x0 0x24010000 0x0 0x10000>;
         interrupts = 	<GIC_SPI 46 IRQ_TYPE_EDGE_RISING>, //jpu
						<GIC_SPI 47 IRQ_TYPE_EDGE_RISING>,
						<GIC_SPI 48 IRQ_TYPE_EDGE_RISING>,
						<GIC_SPI 49 IRQ_TYPE_EDGE_RISING>,
						<GIC_SPI 45 IRQ_TYPE_EDGE_RISING>, //vpu
						<GIC_SPI 39 IRQ_TYPE_EDGE_RISING>,
						<GIC_SPI 42 IRQ_TYPE_EDGE_RISING>;
	};
	rtc {
		compatible = "cvitek,rtc";
		reg = <0x0 0x05026000 0x0 0x1000>,<0x0 0x05025000 0x0 0x1000>;
		//clocks = <&clk CV181X_CLK_RTC_25M>;
		//clock-names = "clk_rtc";
		interrupts = <GIC_SPI 71 IRQ_TYPE_LEVEL_HIGH>;
		interrupt-names = "rtc";
	};
	rgn {
		compatible = "cvitek,rgn";
	};

	pwm0: pwm@27050000 {
		compatible = "cvitek,cvi-pwm";
		reg = <0x0 0x27050000 0x0 0x1000>;
		clocks = <&clk CV186X_CLK_PWM>;
		#pwm-cells = <2>;
	};

	pwm1: pwm@27051000 {
		compatible = "cvitek,cvi-pwm";
		reg = <0x0 0x27051000 0x0 0x1000>;
		clocks = <&clk CV186X_CLK_PWM>;
		#pwm-cells = <2>;
	};

	pwm2: pwm@27052000 {
		compatible = "cvitek,cvi-pwm";
		reg = <0x0 0x27052000 0x0 0x1000>;
		clocks = <&clk CV186X_CLK_PWM>;
		#pwm-cells = <2>;
	};

	pwm3: pwm@27053000 {
		compatible = "cvitek,cvi-pwm";
		reg = <0x0 0x27053000 0x0 0x1000>;
		clocks = <&clk CV186X_CLK_PWM>;
		#pwm-cells = <2>;
	};

	pwm4: pwm@27054000 {
		compatible = "cvitek,cvi-pwm";
		reg = <0x0 0x27054000 0x0 0x1000>;
		clocks = <&clk CV186X_CLK_PWM>;
		#pwm-cells = <2>;
	};

	saradc {
		compatible = "cvitek,saradc";
		reg-names = "top_domain_saradc", "rtc_domain_saradc";
		reg = <0x0 0x270E0000 0x0 0x1000>, <0x0 0x0502C000 0x0 0x1000>;
		clocks = <&clk CV186X_CLK_SARADC>;
		clock-names = "clk_saradc";
		resets = <&rst RST_SARADC>;
		reset-names = "res_saradc";
		interrupts = <GIC_SPI 162 IRQ_TYPE_EDGE_RISING>;
	};

	thermal:thermal@270D0000 {
		compatible = "cvitek,cv186x-thermal";
		reg = <0x0 0x270D0000 0x0 0x10000>;
		clocks = <&clk CV186X_CLK_TEMPSEN>;
		clock-names = "clk_tempsen";
		reset-names = "tempsen";
		#thermal-sensor-cells = <1>;
	};

	thermal-zones {
		soc_thermal_0: soc_thermal_0 {
			polling-delay-passive = <1000>; /* milliseconds */
			polling-delay = <1000>; /* milliseconds */
			thermal-sensors = <&thermal 0>;

			trips {
				soc_thermal_trip_0: soc_thermal_trip_0 {
					temperature = <110000>; /* millicelsius */
					hysteresis = <10000>; /* millicelsius */
					type = "passive";
				};

				soc_thermal_trip_1: soc_thermal_trip_1 {
					temperature = <120000>; /* millicelsius */
					hysteresis = <20000>; /* millicelsius */
					type = "passive";
				};

				soc_thermal_crtical_0: soc_thermal_crtical_0 {
					temperature = <125000>; /* millicelsius */
					hysteresis = <0>; /* millicelsius */
					type = "critical";
				};
			};
		};
	};

	sophgo-cooling {
		clocks = <&clk CV186X_AP_CPU_CLK>, <&clk CV186X_TPU_CLK_TPU>;
		clock-names = "clk_cpu", "clk_tpu_axi";
		dev-freqs = <1600000000 1000000000>,
			<1000000000 800000000>,
			<1000000000 100000000>;
		compatible = "cvitek,cv186x-cooling";
		#cooling-cells = <2>;
	};

	pinctrl {
		compatible = "cvitek,pinctrl-sophgo";
		reg = <0 0x28104100 0 0x100>,
			<0 0x28104500 0 0x100>,
			<0 0x28104600 0 0x100>,
			<0 0x05027000 0 0x100>,
			<0 0x28104800 0 0x100>,
			<0 0x28104900 0 0x100>,
			<0 0x28104b00 0 0x100>,
			<0 0x28104c00 0 0x100>,
			<0 0x28104e00 0 0x100>,
			<0 0x28105000 0 0x100>,
			<0 0x28105300 0 0x100>,
			<0 0x28105600 0 0x100>;
	};

	irrx:irrx@0502E000 {
		compatible = "cvitek,irrx";
		reg = <0x0 0x0502E000 0x0 0x1000>;
		interrupts = <GIC_SPI 75 IRQ_TYPE_EDGE_RISING>;
	};

	keyscan:keyscan@27030000 {
		compatible = "cvitek,keyscan";
		reg = <0x0 0x27030000 0x0 0x10000>;
		interrupts = <GIC_SPI 151 IRQ_TYPE_EDGE_RISING>;
		clocks	= <&clk CV186X_CLK_KEYSCAN>;
		resets = <&rst RST_KEYSCAN>;
		reset-names = "res_keyscan";
		keypad,num-rows = <4>;
		keypad,num-columns = <4>;
		mode = <1>;

		// row << 24 | column << 16 | key-code
		linux,keymap = < MATRIX_KEY(0x00, 0x00, KEY_F13)
				MATRIX_KEY(0x00, 0x01, KEY_F9)
				MATRIX_KEY(0x00, 0x02, KEY_F5)
				MATRIX_KEY(0x00, 0x03, KEY_F1)
				MATRIX_KEY(0x01, 0x00, KEY_F14)
				MATRIX_KEY(0x01, 0x01, KEY_F10)
				MATRIX_KEY(0x01, 0x02, KEY_F6)
				MATRIX_KEY(0x01, 0x03, KEY_F2)
				MATRIX_KEY(0x02, 0x00, KEY_F15)
				MATRIX_KEY(0x02, 0x01, KEY_F11)
				MATRIX_KEY(0x02, 0x02, KEY_F7)
				MATRIX_KEY(0x02, 0x03, KEY_F3)
				MATRIX_KEY(0x03, 0x00, KEY_F16)
				MATRIX_KEY(0x03, 0x01, KEY_F12)
				MATRIX_KEY(0x03, 0x02, KEY_F8)
				MATRIX_KEY(0x03, 0x03, KEY_F4) >;
	};
};

